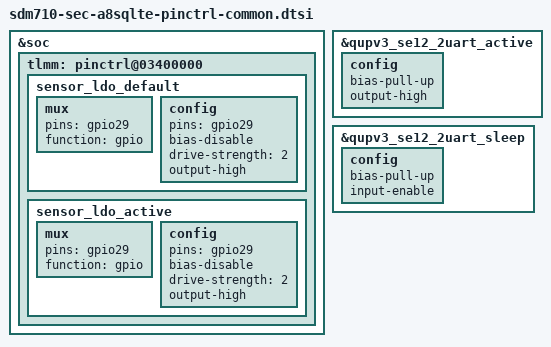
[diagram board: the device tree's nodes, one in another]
/* Copyright (c) 2016-2018, The Linux Foundation. All rights reserved.
 *
 * This program is free software; you can redistribute it and/or modify
 * it under the terms of the GNU General Public License version 2 and
 * only version 2 as published by the Free Software Foundation.
 *
 * This program is distributed in the hope that it will be useful,
 * but WITHOUT ANY WARRANTY; without even the implied warranty of
 * MERCHANTABILITY or FITNESS FOR A PARTICULAR PURPOSE.  See the
 * GNU General Public License for more details.
 */

&soc {
	tlmm: pinctrl@03400000 {
		sensor_ldo_default: sensor_ldo_default {
			mux {
				pins = "gpio29";
				function = "gpio";
			};

			config {
				pins = "gpio29";
				bias-disable; /* No PULL */
				drive-strength = <2>; /* 2 MA */
				output-high;
			};
		};

		sensor_ldo_active: sensor_ldo_active {
			mux {
				pins = "gpio29";
				function = "gpio";
			};

			config {
				pins = "gpio29";
				bias-disable; /* No PULL */
				drive-strength = <2>; /* 2 MA */
				output-high;
			};
		};
	};
};

&qupv3_se12_2uart_active {
	config {
		/delete-property/bias-disable;
		bias-pull-up;
		output-high;
	};
};

&qupv3_se12_2uart_sleep {
	config {
		/delete-property/bias-pull-down;
		bias-pull-up;
		input-enable;
	};
};
